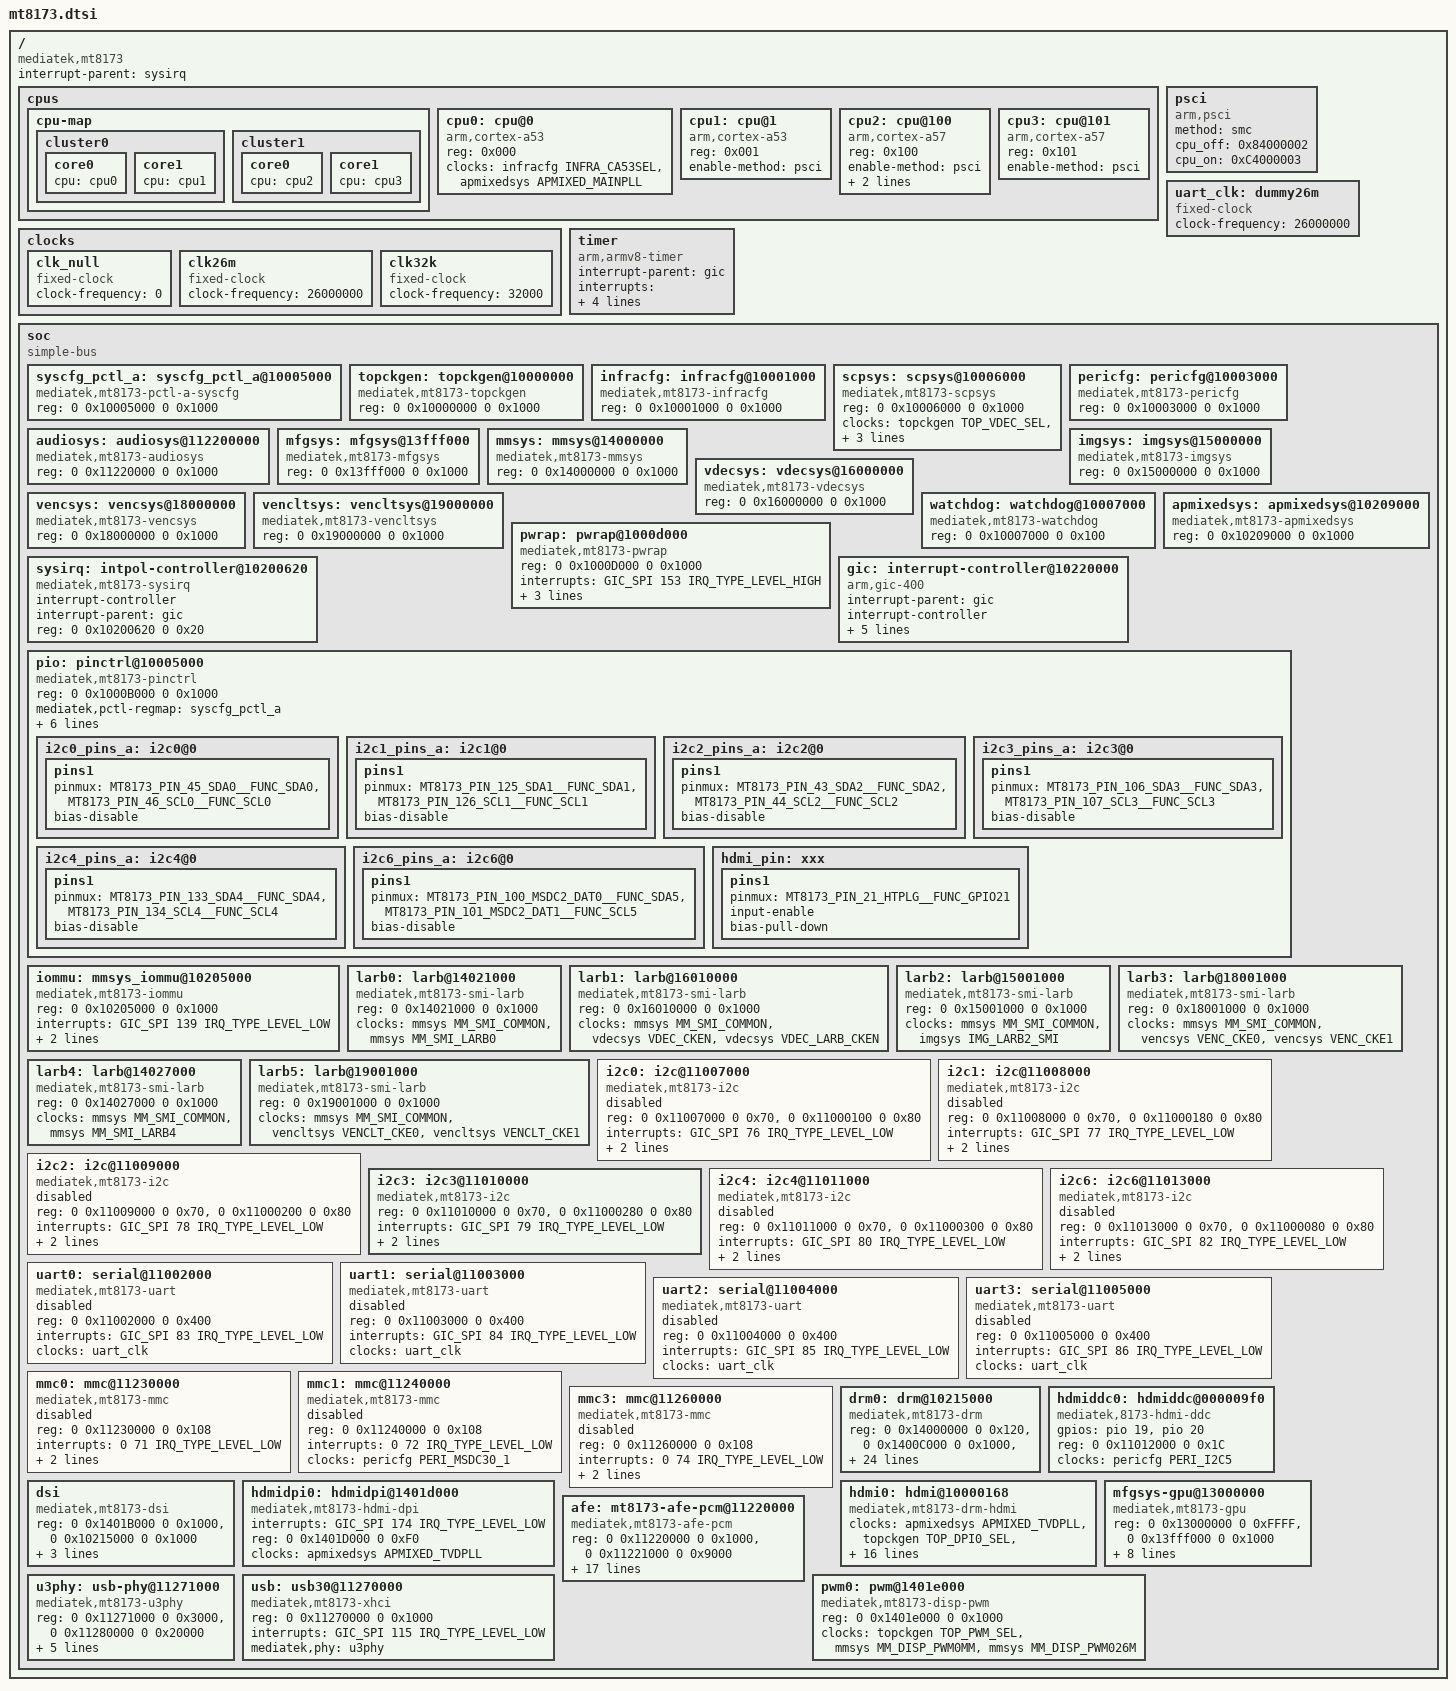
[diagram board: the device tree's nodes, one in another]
/*
 * Copyright (c) 2014 MediaTek Inc.
 * Author: Eddie Huang <eddie.huang@mediatek.com>
 *
 * This program is free software; you can redistribute it and/or modify
 * it under the terms of the GNU General Public License version 2 as
 * published by the Free Software Foundation.
 *
 * This program is distributed in the hope that it will be useful,
 * MERCHANTABILITY or FITNESS FOR A PARTICULAR PURPOSE.  See the
 * GNU General Public License for more details.
 */

#include <dt-bindings/interrupt-controller/irq.h>
#include <dt-bindings/interrupt-controller/arm-gic.h>
#include <dt-bindings/reset-controller/mt8173-resets.h>
#include <dt-bindings/power/mt8173-power.h>
#include <dt-bindings/clock/mt8173-clk.h>
#include <dt-bindings/iommu/mt8173-iommu-port.h>
#include "mt8173-pinfunc.h"

/ {
	compatible = "mediatek,mt8173";
	interrupt-parent = <&sysirq>;
	#address-cells = <2>;
	#size-cells = <2>;

	cpus {
		#address-cells = <1>;
		#size-cells = <0>;

		cpu-map {
			cluster0 {
				core0 {
					cpu = <&cpu0>;
				};
				core1 {
					cpu = <&cpu1>;
				};
			};

			cluster1 {
				core0 {
					cpu = <&cpu2>;
				};
				core1 {
					cpu = <&cpu3>;
				};
			};
		};

		cpu0: cpu@0 {
			device_type = "cpu";
			compatible = "arm,cortex-a53";
			reg = <0x000>;
			clocks = <&infracfg INFRA_CA53SEL>,
				 <&apmixedsys APMIXED_MAINPLL>;
			clock-names = "cpu", "intermediate";
		};

		cpu1: cpu@1 {
			device_type = "cpu";
			compatible = "arm,cortex-a53";
			reg = <0x001>;
			enable-method = "psci";
		};

		cpu2: cpu@100 {
			device_type = "cpu";
			compatible = "arm,cortex-a57";
			reg = <0x100>;
			enable-method = "psci";
			clocks = <&infracfg INFRA_CA57SEL>,
				 <&apmixedsys APMIXED_MAINPLL>;
			clock-names = "cpu", "intermediate";
		};

		cpu3: cpu@101 {
			device_type = "cpu";
			compatible = "arm,cortex-a57";
			reg = <0x101>;
			enable-method = "psci";
		};
	};

	psci {
		compatible = "arm,psci";
		method = "smc";
		cpu_off	      = <0x84000002>;
		cpu_on	      = <0xC4000003>;
	};

	clocks {
		clk_null: clk_null {
			compatible = "fixed-clock";
			#clock-cells = <0>;
			clock-frequency = <0>;
		};

		clk26m: clk26m {
			compatible = "fixed-clock";
			#clock-cells = <0>;
			clock-frequency = <26000000>;
		};

		clk32k: clk32k {
			compatible = "fixed-clock";
			#clock-cells = <0>;
			clock-frequency = <32000>;
		};
	};

	uart_clk: dummy26m {
		compatible = "fixed-clock";
		clock-frequency = <26000000>;
		#clock-cells = <0>;
	};

	timer {
		compatible = "arm,armv8-timer";
		interrupt-parent = <&gic>;
		interrupts = <GIC_PPI 13
			     (GIC_CPU_MASK_SIMPLE(4) | IRQ_TYPE_LEVEL_LOW)>,
			     <GIC_PPI 14
			     (GIC_CPU_MASK_SIMPLE(4) | IRQ_TYPE_LEVEL_LOW)>,
			     <GIC_PPI 11
			     (GIC_CPU_MASK_SIMPLE(4) | IRQ_TYPE_LEVEL_LOW)>,
			     <GIC_PPI 10
			     (GIC_CPU_MASK_SIMPLE(4) | IRQ_TYPE_LEVEL_LOW)>;
	};

	soc {
		#address-cells = <2>;
		#size-cells = <2>;
		compatible = "simple-bus";
		ranges;

		syscfg_pctl_a: syscfg_pctl_a@10005000 {
			compatible = "mediatek,mt8173-pctl-a-syscfg", "syscon";
			reg = <0 0x10005000 0 0x1000>;
		};

		topckgen: topckgen@10000000 {
			compatible = "mediatek,mt8173-topckgen";
			reg = <0 0x10000000 0 0x1000>;
			#clock-cells = <1>;
		};

		infracfg: infracfg@10001000 {
			compatible = "mediatek,mt8173-infracfg", "syscon";
			reg = <0 0x10001000 0 0x1000>;
			#clock-cells = <1>;
			#reset-cells = <1>;
		};

		scpsys: scpsys@10006000 {
			compatible = "mediatek,mt8173-scpsys";
			#power-domain-cells = <1>;
			reg = <0 0x10006000 0 0x1000>;
			clocks = <&topckgen TOP_VDEC_SEL>,
				 <&topckgen TOP_MFG_SEL>,
				 <&topckgen TOP_VENC_SEL>,
				 <&topckgen TOP_MM_SEL>,
				 <&topckgen TOP_VENC_LT_SEL>;
			clock-names = "vdec", "mfg", "venc", "disp", "ven2";
		};

		pericfg: pericfg@10003000 {
			compatible = "mediatek,mt8173-pericfg", "syscon";
			reg = <0 0x10003000 0 0x1000>;
			#clock-cells = <1>;
			#reset-cells = <1>;
		};

		audiosys: audiosys@112200000 {
			compatible = "mediatek,mt8173-audiosys", "syscon";
			reg = <0 0x11220000 0 0x1000>;
			#clock-cells = <1>;
		};

		mfgsys: mfgsys@13fff000 {
			compatible = "mediatek,mt8173-mfgsys", "syscon";
			reg = <0 0x13fff000 0 0x1000>;
			#clock-cells = <1>;
		};

		mmsys: mmsys@14000000 {
			compatible = "mediatek,mt8173-mmsys", "syscon";
			reg = <0 0x14000000 0 0x1000>;
			#clock-cells = <1>;
		};

		imgsys: imgsys@15000000 {
			compatible = "mediatek,mt8173-imgsys", "syscon";
			reg = <0 0x15000000 0 0x1000>;
			#clock-cells = <1>;
		};

		vdecsys: vdecsys@16000000 {
			compatible = "mediatek,mt8173-vdecsys", "syscon";
			reg = <0 0x16000000 0 0x1000>;
			#clock-cells = <1>;
		};

		vencsys: vencsys@18000000 {
			compatible = "mediatek,mt8173-vencsys", "syscon";
			reg = <0 0x18000000 0 0x1000>;
			#clock-cells = <1>;
		};

		vencltsys: vencltsys@19000000 {
			compatible = "mediatek,mt8173-vencltsys", "syscon";
			reg = <0 0x19000000 0 0x1000>;
			#clock-cells = <1>;
		};

		watchdog: watchdog@10007000 {
			compatible = "mediatek,mt8173-watchdog",
				     "mediatek,mt6589-wdt";
			reg = <0 0x10007000 0 0x100>;
		};

		pwrap: pwrap@1000d000 {
			compatible = "mediatek,mt8173-pwrap";
			reg = <0 0x1000D000 0 0x1000>;
			reg-names = "pwrap";
			interrupts = <GIC_SPI 153 IRQ_TYPE_LEVEL_HIGH>;
			resets = <&infracfg MT8173_INFRA_PMIC_WRAP_RST>;
			reset-names = "pwrap";
			clocks = <&infracfg INFRA_PMICSPI>,
				 <&infracfg INFRA_PMICWRAP>;
			clock-names = "spi", "wrap";
		};

		apmixedsys: apmixedsys@10209000 {
			compatible = "mediatek,mt8173-apmixedsys";
			reg = <0 0x10209000 0 0x1000>;
			#clock-cells = <1>;
		};

		sysirq: intpol-controller@10200620 {
			compatible = "mediatek,mt8173-sysirq",
				     "mediatek,mt6577-sysirq";
			interrupt-controller;
			#interrupt-cells = <3>;
			interrupt-parent = <&gic>;
			reg = <0 0x10200620 0 0x20>;
		};

		gic: interrupt-controller@10220000 {
			compatible = "arm,gic-400";
			#interrupt-cells = <3>;
			interrupt-parent = <&gic>;
			interrupt-controller;
			reg = <0 0x10221000 0 0x1000>,
			      <0 0x10222000 0 0x2000>,
			      <0 0x10224000 0 0x2000>,
			      <0 0x10226000 0 0x2000>;
			interrupts = <GIC_PPI 9
				(GIC_CPU_MASK_SIMPLE(4) | IRQ_TYPE_LEVEL_HIGH)>;
		};

		pio: pinctrl@10005000 {
			compatible = "mediatek,mt8173-pinctrl";
			reg = <0 0x1000B000 0 0x1000>;
			mediatek,pctl-regmap = <&syscfg_pctl_a>;
			pins-are-numbered;
			gpio-controller;
			#gpio-cells = <2>;
			interrupt-controller;
			#interrupt-cells = <2>;
			interrupts = <GIC_SPI 145 IRQ_TYPE_LEVEL_HIGH>,
				     <GIC_SPI 146 IRQ_TYPE_LEVEL_HIGH>,
				     <GIC_SPI 147 IRQ_TYPE_LEVEL_HIGH>;

			i2c0_pins_a: i2c0@0 {
				pins1 {
					pinmux = <MT8173_PIN_45_SDA0__FUNC_SDA0>,
						 <MT8173_PIN_46_SCL0__FUNC_SCL0>;
					bias-disable;
				};
			};

			i2c1_pins_a: i2c1@0 {
				pins1 {
					pinmux = <MT8173_PIN_125_SDA1__FUNC_SDA1>,
						 <MT8173_PIN_126_SCL1__FUNC_SCL1>;
					bias-disable;
				};
			};

			i2c2_pins_a: i2c2@0 {
				pins1 {
					pinmux = <MT8173_PIN_43_SDA2__FUNC_SDA2>,
						 <MT8173_PIN_44_SCL2__FUNC_SCL2>;
					bias-disable;
				};
			};

			i2c3_pins_a: i2c3@0 {
				pins1 {
					pinmux = <MT8173_PIN_106_SDA3__FUNC_SDA3>,
						 <MT8173_PIN_107_SCL3__FUNC_SCL3>;
					bias-disable;
				};
			};

			i2c4_pins_a: i2c4@0 {
				pins1 {
					pinmux = <MT8173_PIN_133_SDA4__FUNC_SDA4>,
						 <MT8173_PIN_134_SCL4__FUNC_SCL4>;
					bias-disable;
				};
			};

			i2c6_pins_a: i2c6@0 {
				pins1 {
					pinmux = <MT8173_PIN_100_MSDC2_DAT0__FUNC_SDA5>,
						 <MT8173_PIN_101_MSDC2_DAT1__FUNC_SCL5>;
					bias-disable;
				};
			};

			hdmi_pin:xxx {
				pins1 {
					pinmux = <MT8173_PIN_21_HTPLG__FUNC_GPIO21>;
					input-enable;
					bias-pull-down;
				};
			};
		};

		iommu: mmsys_iommu@10205000 {
			compatible = "mediatek,mt8173-iommu";
			reg = <0 0x10205000 0 0x1000>;
			interrupts = <GIC_SPI 139 IRQ_TYPE_LEVEL_LOW>;
			clocks = <&infracfg INFRA_M4U>;
			clock-names = "infra_m4u";
			larb = <&larb0 &larb1 &larb2 &larb3 &larb4 &larb5>;
			#iommu-cells = <1>;
		};

		larb0:larb@14021000 {
			compatible = "mediatek,mt8173-smi-larb";
			reg = <0 0x14021000 0 0x1000>;
			clocks = <&mmsys MM_SMI_COMMON>, <&mmsys MM_SMI_LARB0>;
			clock-names = "larb_sub0", "larb_sub1";
		};

		larb1:larb@16010000 {
			compatible = "mediatek,mt8173-smi-larb";
			reg = <0 0x16010000 0 0x1000>;
			clocks = <&mmsys MM_SMI_COMMON>,
					<&vdecsys VDEC_CKEN>,
					<&vdecsys VDEC_LARB_CKEN>;
			clock-names = "larb_sub0", "larb_sub1", "larb_sub2";
		};

		larb2:larb@15001000 {
			compatible = "mediatek,mt8173-smi-larb";
			reg = <0 0x15001000 0 0x1000>;
			clocks = <&mmsys MM_SMI_COMMON>,
					<&imgsys IMG_LARB2_SMI>;
			clock-names = "larb_sub0", "larb_sub1";
		};

		larb3:larb@18001000 {
			compatible = "mediatek,mt8173-smi-larb";
			reg = <0 0x18001000 0 0x1000>;
			clocks = <&mmsys MM_SMI_COMMON>,
					<&vencsys VENC_CKE0>,
					<&vencsys VENC_CKE1>;
			clock-names = "larb_sub0", "larb_sub1", "larb_sub2";
		};

		larb4:larb@14027000 {
			compatible = "mediatek,mt8173-smi-larb";
			reg = <0 0x14027000 0 0x1000>;
			clocks = <&mmsys MM_SMI_COMMON>, <&mmsys MM_SMI_LARB4>;
			clock-names = "larb_sub0", "larb_sub1";
		};

		larb5:larb@19001000 {
			compatible = "mediatek,mt8173-smi-larb";
			reg = <0 0x19001000 0 0x1000>;
			clocks = <&mmsys MM_SMI_COMMON>,
					<&vencltsys VENCLT_CKE0>,
					<&vencltsys VENCLT_CKE1>;
			clock-names = "larb_sub0", "larb_sub1", "larb_sub2";
		};

		i2c0: i2c@11007000 {
			compatible = "mediatek,mt8173-i2c";
			reg = <0 0x11007000 0 0x70>,
			      <0 0x11000100 0 0x80>;
			interrupts = <GIC_SPI 76 IRQ_TYPE_LEVEL_LOW>;
			clock-div = <16>;
			clocks = <&pericfg PERI_I2C0>, <&pericfg PERI_AP_DMA>;
			clock-names = "main", "dma";
			status = "disabled";
		};

		i2c1: i2c@11008000 {
			compatible = "mediatek,mt8173-i2c";
			reg = <0 0x11008000 0 0x70>,
			      <0 0x11000180 0 0x80>;
			interrupts = <GIC_SPI 77 IRQ_TYPE_LEVEL_LOW>;
			clock-div = <16>;
			clocks = <&pericfg PERI_I2C1>, <&pericfg PERI_AP_DMA>;
			clock-names = "main", "dma";
			status = "disabled";
		};

		i2c2: i2c@11009000 {
			compatible = "mediatek,mt8173-i2c";
			reg = <0 0x11009000 0 0x70>,
			      <0 0x11000200 0 0x80>;
			interrupts = <GIC_SPI 78 IRQ_TYPE_LEVEL_LOW>;
			clock-div = <16>;
			clocks = <&pericfg PERI_I2C2>, <&pericfg PERI_AP_DMA>;
			clock-names = "main", "dma";
			status = "disabled";
		};

		i2c3: i2c3@11010000 {
			compatible = "mediatek,mt8173-i2c";
			reg = <0 0x11010000 0 0x70>,
			      <0 0x11000280 0 0x80>;
			interrupts = <GIC_SPI 79 IRQ_TYPE_LEVEL_LOW>;
			clock-div = <16>;
			clocks = <&pericfg PERI_I2C3>, <&pericfg PERI_AP_DMA>;
			clock-names = "main", "dma";
		};

		i2c4: i2c4@11011000 {
			compatible = "mediatek,mt8173-i2c";
			reg = <0 0x11011000 0 0x70>,
			      <0 0x11000300 0 0x80>;
			interrupts = <GIC_SPI 80 IRQ_TYPE_LEVEL_LOW>;
			clock-div = <16>;
			clocks = <&pericfg PERI_I2C4>, <&pericfg PERI_AP_DMA>;
			clock-names = "main", "dma";
			status = "disabled";
		};

		i2c6: i2c6@11013000 {
			compatible = "mediatek,mt8173-i2c";
			reg = <0 0x11013000 0 0x70>,
			      <0 0x11000080 0 0x80>;
			interrupts = <GIC_SPI 82 IRQ_TYPE_LEVEL_LOW>;
			clock-div = <16>;
			clocks = <&pericfg PERI_I2C6>, <&pericfg PERI_AP_DMA>;
			clock-names = "main", "dma";
			status = "disabled";
		};

		uart0: serial@11002000 {
			compatible = "mediatek,mt8173-uart",
				     "mediatek,mt6577-uart";
			reg = <0 0x11002000 0 0x400>;
			interrupts = <GIC_SPI 83 IRQ_TYPE_LEVEL_LOW>;
			clocks = <&uart_clk>;
			status = "disabled";
		};

		uart1: serial@11003000 {
			compatible = "mediatek,mt8173-uart",
				     "mediatek,mt6577-uart";
			reg = <0 0x11003000 0 0x400>;
			interrupts = <GIC_SPI 84 IRQ_TYPE_LEVEL_LOW>;
			clocks = <&uart_clk>;
			status = "disabled";
		};

		uart2: serial@11004000 {
			compatible = "mediatek,mt8173-uart",
				     "mediatek,mt6577-uart";
			reg = <0 0x11004000 0 0x400>;
			interrupts = <GIC_SPI 85 IRQ_TYPE_LEVEL_LOW>;
			clocks = <&uart_clk>;
			status = "disabled";
		};

		uart3: serial@11005000 {
			compatible = "mediatek,mt8173-uart",
				     "mediatek,mt6577-uart";
			reg = <0 0x11005000 0 0x400>;
			interrupts = <GIC_SPI 86 IRQ_TYPE_LEVEL_LOW>;
			clocks = <&uart_clk>;
			status = "disabled";
		};

		mmc0: mmc@11230000 {
			compatible = "mediatek,mt8173-mmc",
				     "mediatek,mt8135-mmc";
			reg = <0 0x11230000 0 0x108>;
			interrupts = <0 71 IRQ_TYPE_LEVEL_LOW>;
			clocks = <&pericfg PERI_MSDC30_0>,
				 <&topckgen TOP_MSDC50_0_H_SEL>;
			clock-names = "source", "hclk";
			status = "disabled";
		};

		mmc1: mmc@11240000 {
			compatible = "mediatek,mt8173-mmc",
				     "mediatek,mt8135-mmc";
			reg = <0 0x11240000 0 0x108>;
			interrupts = <0 72 IRQ_TYPE_LEVEL_LOW>;
			clocks = <&pericfg PERI_MSDC30_1>;
			clock-names = "source";
			status = "disabled";
		};

		mmc3: mmc@11260000 {
			compatible = "mediatek,mt8173-mmc",
				     "mediatek,mt8135-mmc";
			reg = <0 0x11260000 0 0x108>;
			interrupts = <0 74 IRQ_TYPE_LEVEL_LOW>;
			clocks = <&pericfg PERI_MSDC30_3>,
				 <&topckgen TOP_MSDC50_2_H_SEL>;
			clock-names = "source", "hclk";
			status = "disabled";
		};

		drm0: drm@10215000 {
			compatible = "mediatek,mt8173-drm";
			reg = <0 0x14000000 0 0x120>,	/* CONFIG */
			      <0 0x1400C000 0 0x1000>,	/* OVL0 */
			      <0 0x1400D000 0 0x1000>,	/* OVL1 */
			      <0 0x1400E000 0 0x1000>,	/* RDMA0 */
			      <0 0x1400F000 0 0x1000>,	/* RDMA1 */
			      <0 0x14013000 0 0x1000>,	/* COLOR0 */
			      <0 0x14014000 0 0x1000>,	/* COLOR1 */
			      <0 0x14015000 0 0x1000>,	/* AAL */
			      <0 0x14016000 0 0x1000>,	/* GAMMA */
			      <0 0x1401A000 0 0x1000>,	/* UFOE */
			      <0 0x14020000 0 0x1000>,	/* MUTEX */
			      <0 0x14023000 0 0x1000>;	/* OD */
			#interrupts = <0 182 0x8>;	/* RDMA */
			interrupts = <0 196 0x8>;	/* OD */
			larb = <&larb0>, <&larb4>;
			iommus = <&iommu M4U_PORT_DISP_OVL0>,
				<&iommu M4U_PORT_DISP_RDMA0>,
				<&iommu M4U_PORT_DISP_OVL1>,
				<&iommu M4U_PORT_DISP_RDMA1>;
			power-domains = <&scpsys MT8173_POWER_DOMAIN_DIS>;
			clocks = <&mmsys MM_MUTEX_32K>,
				 <&mmsys MM_DISP_OVL0>,
				 <&mmsys MM_DISP_OVL1>,
				 <&mmsys MM_DISP_RDMA0>,
				 <&mmsys MM_DISP_RDMA1>,
				 <&mmsys MM_DISP_COLOR0>,
				 <&mmsys MM_DISP_COLOR1>,
				 <&mmsys MM_DISP_AAL>,
				 <&mmsys MM_DISP_GAMMA>,
				 <&mmsys MM_DISP_UFOE>,
				 <&mmsys MM_DISP_OD>;
			clock-names = "mutex_disp_ck",
				      "ovl0_disp_ck",
				      "ovl1_disp_ck",
				      "rdma0_disp_ck",
				      "rdma1_disp_ck",
				      "color0_disp_ck",
				      "color1_disp_ck",
				      "aal_disp_ck",
				      "gamma_disp_ck",
				      "ufoe_disp_ck",
				      "od_disp_ck";
			connectors = <&dsi>, <&hdmi0>;
		};

		hdmiddc0:hdmiddc@000009f0 {
			compatible = "mediatek,8173-hdmi-ddc";
			gpios = <&pio 19 GPIO_ACTIVE_HIGH>, /* hdmi sck */
				<&pio 20 GPIO_ACTIVE_HIGH>; /* hdmi sd  */
			reg = <0 0x11012000 0 0x1C>;
			clocks = <&pericfg PERI_I2C5>;
			clock-names = "ddc-i2c";
		};

		dsi: dsi {
			compatible = "mediatek,mt8173-dsi";
			reg = <0 0x1401B000 0 0x1000>,	/* DSI0 */
				<0 0x10215000 0 0x1000>;  /* MIPITX */
			clocks = <&mmsys MM_DSI0_ENGINE>,	<&mmsys MM_DSI0_DIGITAL>;
			clock-names = "dsi0_engine_disp_ck", "dsi0_digital_disp_ck";
			disp-bdg-supply = <&mt6397_vgp2_reg>;
		};


		hdmidpi0:hdmidpi@1401d000{
			compatible = "mediatek,mt8173-hdmi-dpi";
			interrupts = <GIC_SPI 174 IRQ_TYPE_LEVEL_LOW>;
			reg = <0 0x1401D000 0 0xF0>;
			clocks = <&apmixedsys APMIXED_TVDPLL>;
		};

		hdmi0:hdmi@10000168{
			compatible = "mediatek,mt8173-drm-hdmi";
			clocks = <&apmixedsys APMIXED_TVDPLL>,
				 <&topckgen TOP_DPI0_SEL>,
				 <&topckgen TOP_TVDPLL_D2>,
				 <&topckgen TOP_TVDPLL_D4>,
				 <&topckgen TOP_TVDPLL_D8>,
				 <&topckgen TOP_HDMI_SEL>,
				 <&topckgen TOP_HDMITX_DIG_CTS>,
				 <&topckgen TOP_HDMITXPLL_D2>,
				 <&topckgen TOP_HDMITXPLL_D3>,
				 <&mmsys MM_HDMI_PIXEL>,
				 <&mmsys MM_HDMI_PLLCK>,
				 <&mmsys MM_DPI_PIXEL>,
				 <&mmsys MM_DPI_ENGINE>,
				 <&mmsys MM_HDMI_AUDIO>,
				 <&mmsys MM_HDMI_SPDIF>;
			clock-names = "tvdpll-clk",
				      "dpi-clk-mux",
				      "dpi-clk-div2",
				      "dpi-clk-div4",
				      "dpi-clk-div8",
				      "hdmitx-clk-mux",
				      "hdmitx-clk-div1",
				      "hdmitx-clk-div2",
				      "hdmitx-clk-div3",
				      "hdmi-id-clk-gate",
				      "hdmi-pll-clk-gate",
				      "dpi-clk-gate",
				      "dpi-eng-clk-gate",
				      "aud-bclk-gate",
				      "aud-spdif-gate";
			prenode = <&hdmidpi0>;
			i2cnode = <&hdmiddc0>;
			gpios = <&pio 42 GPIO_ACTIVE_HIGH>, /* flt_n_5v */
				<&pio 127 GPIO_ACTIVE_HIGH>,/* 5v enable */
				<&pio 21 GPIO_ACTIVE_HIGH>; /* htplg */
			reg = <0 0x14000900 0 0x8>,
				<0 0x10209100 0 0x20>,
				<0 0x14025000 0 0x400>;
			pinctrl-names = "default";
			pinctrl-0 = <&hdmi_pin>;
		};

		mfgsys-gpu@13000000 {
			compatible = "mediatek,mt8173-gpu";
			reg = <0 0x13000000 0 0xFFFF>, <0 0x13fff000 0 0x1000>;
			mfgsys-power-supply = <&mt6397_vgpu_reg>;
			power-domains =	<&scpsys MT8173_POWER_DOMAIN_MFG>;
			clocks = <&apmixedsys APMIXED_MMPLL>,
				 <&topckgen TOP_MEM_MFG_IN_SEL>,
				 <&topckgen TOP_AXI_MFG_IN_SEL>,
				 <&mfgsys MFG_AXI>,
				 <&mfgsys MFG_MEM>,
				 <&mfgsys MFG_G3D>,
				 <&mfgsys MFG_26M>;

			clock-names = "mmpll_clk",
				      "mfg_mem_in_sel",
				      "mfg_axi_in_sel",
				      "mfg_axi",
				      "mfg_mem",
				      "mfg_g3d",
				      "mfg_26m";

			interrupts = <0 217 IRQ_TYPE_LEVEL_LOW>;
			interrupt-names = "RGX";
		};

		afe: mt8173-afe-pcm@11220000  {
			compatible = "mediatek,mt8173-afe-pcm";
			reg = <0 0x11220000 0 0x1000>,
				  <0 0x11221000 0 0x9000>;
			interrupts = <GIC_SPI 134 IRQ_TYPE_EDGE_FALLING>;
			power-domains = <&scpsys MT8173_POWER_DOMAIN_AUDIO>;
			clocks = <&infracfg INFRA_AUDIO>,
					 <&topckgen TOP_AUDIO_SEL>,
					 <&topckgen TOP_AUD_INTBUS_SEL>,
					 <&topckgen TOP_APLL1_DIV0>,
					 <&topckgen TOP_APLL2_DIV0>,
					 <&topckgen TOP_I2S0_M_CK_SEL>,
					 <&topckgen TOP_I2S1_M_CK_SEL>,
					 <&topckgen TOP_I2S2_M_CK_SEL>,
					 <&topckgen TOP_I2S3_M_CK_SEL>,
					 <&topckgen TOP_I2S3_B_CK_SEL>;
			clock-names = "infra_sys_audio_clk",
						  "top_pdn_audio",
						  "top_pdn_aud_intbus",
						  "bck0",
						  "bck1",
						  "i2s0_m",
						  "i2s1_m",
						  "i2s2_m",
						  "i2s3_m",
						  "i2s3_b";
			assigned-clocks = <&topckgen TOP_AUD_1_SEL>,
					  <&topckgen TOP_AUD_2_SEL>;
			assigned-clock-parents = <&topckgen TOP_APLL1_CK>,
						 <&topckgen TOP_APLL2_CK>;
		};

		u3phy: usb-phy@11271000 {
			compatible = "mediatek,mt8173-u3phy";
			reg = <0 0x11271000 0 0x3000>,
			      <0 0x11280000 0 0x20000>;
			power-domains = <&scpsys MT8173_POWER_DOMAIN_USB>;
			usb-host = <&usb>;
			reg-vusb33-supply = <&mt6397_vusb_reg>;
			usb3_ref_clk = <&apmixedsys>;
			clocks = <&pericfg PERI_USB0>,
				 <&pericfg PERI_USB1>;
			clock-names = "peri_usb0", "peri_usb1";
		};

		usb: usb30@11270000 {
			compatible = "mediatek,mt8173-xhci", "generic-xhci";
			reg = <0 0x11270000 0 0x1000>;
			interrupts = <GIC_SPI 115 IRQ_TYPE_LEVEL_LOW>;
			mediatek,phy = <&u3phy>;
		};

		pwm0: pwm@1401e000 {
			compatible = "mediatek,mt8173-disp-pwm";
			reg = <0 0x1401e000 0 0x1000>;
			#pwm-cells = <2>;
			clocks = <&topckgen TOP_PWM_SEL>,
				 <&mmsys MM_DISP_PWM0MM>,
				 <&mmsys MM_DISP_PWM026M>;
			clock-names = "pwm_sel",
				      "mm_disp_pwm0mm",
				      "mm_disp_pwm026m";
		};
	};
};

